AUTOSAR XML (schema 314)
package /ComponentType
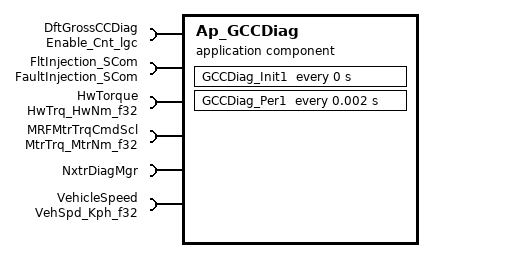
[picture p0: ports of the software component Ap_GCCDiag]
  application software component type Ap_GCCDiag
    6 x require port:
      DftGrossCCDiag: unqueued-receiver-com-spec{data-element=Cnt_lgc, init-value=D_FALSE_CNT_LGC}, required-interface=Enable_Cnt_lgc
      FltInjection_SCom: client-com-spec=FltInjection, required-interface=FaultInjection_SCom
      HwTorque: unqueued-receiver-com-spec{data-element=HwNm_f32, init-value=D_ZERO_ULS_F32}, required-interface=HwTrq_HwNm_f32
      MRFMtrTrqCmdScl: unqueued-receiver-com-spec{data-element=MtrNm_f32, init-value=D_ZERO_ULS_F32}, required-interface=MtrTrq_MtrNm_f32
      NxtrDiagMgr: required-com-specs=[GetNTCActive, GetNTCFailed, GetNTCStatus, SetNTCStatus], required-interface=NxtrDiagMgr
      VehicleSpeed: unqueued-receiver-com-spec{data-element=Kph_f32, init-value=D_ZERO_ULS_F32}, required-interface=VehSpd_Kph_f32
  internal behavior Ap_GCCDiag_InternalBehavior: component=Ap_GCCDiag
    timing event GCCDiag_Init1_InitEvent: start-on-event=GCCDiag_Init1, period=0
    timing event TMT_GCCDiag_Per1: start-on-event=GCCDiag_Per1, period=0.002
    port-api-options:
      enable-take-address=false, indirect-api=false, port=DftGrossCCDiag
      enable-take-address=false, indirect-api=false, port=FltInjection_SCom
      enable-take-address=false, indirect-api=false, port=HwTorque
      enable-take-address=false, indirect-api=false, port=MRFMtrTrqCmdScl
      enable-take-address=false, indirect-api=false, port=NxtrDiagMgr
      enable-take-address=false, indirect-api=false, port=VehicleSpeed
    runnable GCCDiag_Init1
    runnable GCCDiag_Per1
      4 x data read access:
        READ_DftGrossCCDiag_Cnt_lgc: data-element=DftGrossCCDiag.Cnt_lgc
        READ_HwTorque_HwNm_f32: data-element=HwTorque.HwNm_f32
        READ_MRFMtrTrqCmdScl_MtrNm_f32: data-element=MRFMtrTrqCmdScl.MtrNm_f32
        READ_VehicleSpeed_Kph_f32: data-element=VehicleSpeed.Kph_f32
      sync call SC_FltInjection_SCom_FltInjection: operation=FltInjection_SCom.FltInjection, timeout=0
      sync call SC_NxtrDiagMgr_SetNTCStatus: operation=NxtrDiagMgr.SetNTCStatus, timeout=0
  swc implementation Ap_GCCDiag_Implementation: behavior=Ap_GCCDiag_InternalBehavior
    code-descriptors:
      code Code: type=SRC
